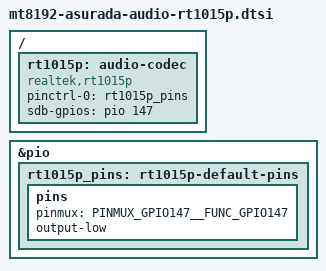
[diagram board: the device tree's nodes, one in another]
// SPDX-License-Identifier: (GPL-2.0 OR MIT)
/*
 * Copyright (C) 2022 MediaTek Inc.
 */

#include <dt-bindings/gpio/gpio.h>
#include <dt-bindings/pinctrl/mt8192-pinfunc.h>

/ {
	rt1015p: audio-codec {
		compatible = "realtek,rt1015p";
		pinctrl-names = "default";
		pinctrl-0 = <&rt1015p_pins>;
		sdb-gpios = <&pio 147 GPIO_ACTIVE_HIGH>;
		#sound-dai-cells = <0>;
	};
};

&pio {
	rt1015p_pins: rt1015p-default-pins {
		pins {
			pinmux = <PINMUX_GPIO147__FUNC_GPIO147>;
			output-low;
		};
	};
};
